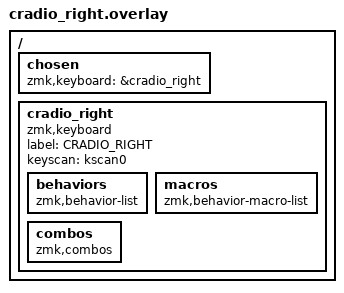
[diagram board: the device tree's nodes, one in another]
/ {
    chosen {
        zmk,keyboard = &cradio_right;
    };
    cradio_right: cradio_right {
        compatible = "zmk,keyboard";
        label = "CRADIO_RIGHT";
        keyscan = <&kscan0>;
        behaviors {
            compatible = "zmk,behavior-list";
        };
        macros {
            compatible = "zmk,behavior-macro-list";
        };
        combos {
            compatible = "zmk,combos";
        };
    };
};
